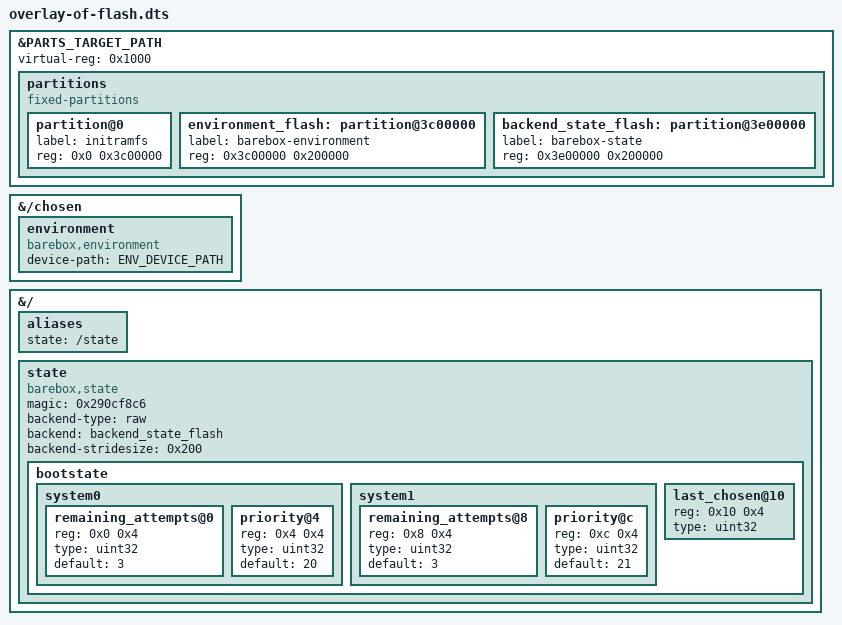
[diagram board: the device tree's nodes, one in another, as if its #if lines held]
/* SPDX-License-Identifier: GPL-2.0-only */

/dts-v1/;
/plugin/;

#ifdef RISCV_VIRT
#define PARTS_TARGET_PATH	/flash@20000000
#define ENV_DEVICE_PATH		"/flash@20000000/partitions/partition@3c00000"
#elif defined ARM_VIRT
#define PARTS_TARGET_PATH	/flash@0
#define ENV_DEVICE_PATH		"/flash@0/partitions/partition@3c00000"
#endif

&{PARTS_TARGET_PATH} {
#ifdef ARM_VIRT
	virtual-reg = <0x1000>;
#endif
	partitions {
		compatible = "fixed-partitions";
		#address-cells = <1>;
		#size-cells = <1>;

		partition@0 {
			label = "initramfs";
			reg = <0x0 0x3c00000>;
		};

		environment_flash: partition@3c00000 {
			label = "barebox-environment";
			reg = <0x3c00000 0x200000>;
		};

		backend_state_flash: partition@3e00000 {
			label = "barebox-state";
			reg = <0x3e00000 0x200000>;
		};
	};
};

&{/chosen} {
	environment {
		compatible = "barebox,environment";
		device-path = ENV_DEVICE_PATH;
	};
};

&{/} {
	aliases {
		state = "/state";
	};

	state {
		#address-cells = <1>;
		#size-cells = <1>;
		compatible = "barebox,state";
		magic = <0x290cf8c6>;
		backend-type = "raw";
		backend = < &backend_state_flash >;
		backend-stridesize = <0x200>;

		bootstate {
			#address-cells = <1>;
			#size-cells = <1>;

			system0 {
				#address-cells = <1>;
				#size-cells = <1>;

				remaining_attempts@0 {
					reg = <0x0 0x4>;
					type = "uint32";
					default = <3>;
				};

				priority@4 {
					reg = <0x4 0x4>;
					type = "uint32";
					default = <20>;
				};
			};

			system1 {
				#address-cells = <1>;
				#size-cells = <1>;

				remaining_attempts@8 {
					reg = <0x8 0x4>;
					type = "uint32";
					default = <3>;
				};

				priority@c {
					reg = <0xc 0x4>;
					type = "uint32";
					default = <21>;
				};
			};

			last_chosen@10 {
				reg = <0x10 0x4>;
				type = "uint32";
			};
		};
	};
};
